VERSION ""

NS_ :

BS_:

BU_:

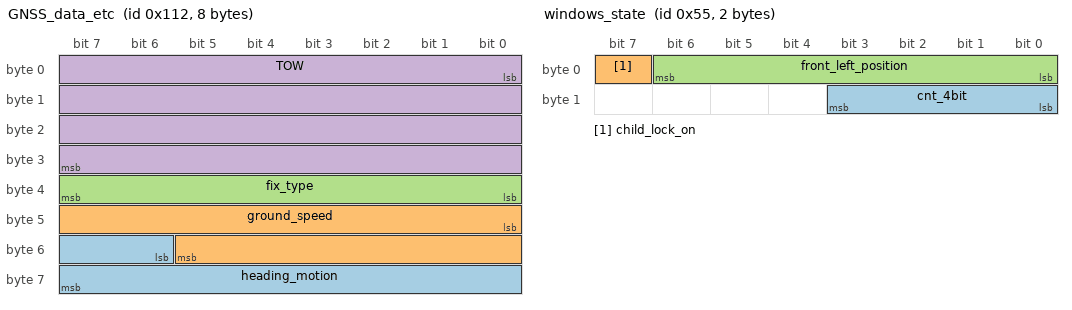
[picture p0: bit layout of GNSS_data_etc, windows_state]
BO_ 274 GNSS_data_etc: 8 Vector__XXX
 SG_ heading_motion : 54|10@1- (1,0) [-512|511] "" Vector__XXX
 SG_ ground_speed : 40|14@1- (0.08,0) [-655.36|655.28] "m/s" Vector__XXX
 SG_ fix_type : 32|8@1+ (1,0) [0|0] "" Vector__XXX
 SG_ TOW : 0|32@1+ (1,0) [0|0] "ms" Vector__XXX

BO_ 511 temperature: 2 Vector__XXX
 SG_ cnt_4bit : 12|4@1+ (1,0) [0|0] "" Vector__XXX
 SG_ temperature : 0|12@1- (0.1,100) [-104.8|304.7] "" Vector__XXX

BO_ 257 DTC_state: 3 Vector__XXX
 SG_ cnt_4bit : 16|4@1+ (1,0) [0|0] "" Vector__XXX
 SG_ stored_error_count : 0|16@1+ (1,0) [0|0] "" Vector__XXX

BO_ 256 error_event: 1 Vector__XXX
 SG_ error_code : 0|8@1+ (1,0) [0|0] "" Vector__XXX

BO_ 85 windows_state: 2 Vector__XXX
 SG_ cnt_4bit : 8|4@1+ (1,0) [0|0] "" Vector__XXX
 SG_ child_lock_on : 7|1@1+ (1,0) [0|0] "" Vector__XXX
 SG_ front_left_position : 0|7@1+ (1,0) [0|127] "%" Vector__XXX

BO_ 273 GNSS_data_pos: 8 Vector__XXX
 SG_ lon : 32|32@1- (1,0) [0|0] "" Vector__XXX
 SG_ lat : 0|32@1- (1,0) [0|0] "" Vector__XXX

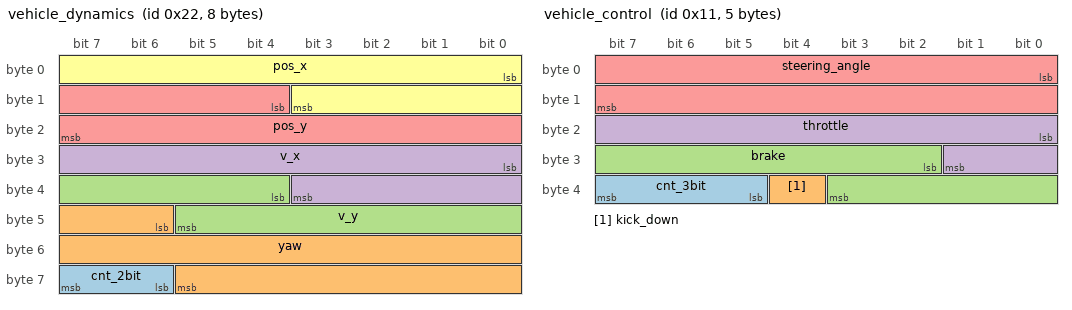
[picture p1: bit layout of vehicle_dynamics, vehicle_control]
BO_ 34 vehicle_dynamics: 8 Vector__XXX
 SG_ cnt_2bit : 62|2@1+ (1,0) [0|0] "" Vector__XXX
 SG_ yaw : 46|16@1- (0.015,0) [-491.52|491.505] "deg" Vector__XXX
 SG_ v_y : 36|10@1- (0.05,0) [-25.6|25.55] "m/s" Vector__XXX
 SG_ v_x : 24|12@1+ (0.1,0) [0|409.5] "m/s" Vector__XXX
 SG_ pos_y : 12|12@1- (1,0) [-2048|2047] "m" Vector__XXX
 SG_ pos_x : 0|12@1- (1,0) [-2048|2047] "m" Vector__XXX

BO_ 17 vehicle_control: 5 Vector__XXX
 SG_ cnt_3bit : 37|3@1+ (1,0) [0|0] "" Vector__XXX
 SG_ kick_down : 36|1@1+ (1,0) [0|0] "" Vector__XXX
 SG_ brake : 26|10@1+ (0.1,0) [0|102.3] "%" Vector__XXX
 SG_ throttle : 16|10@1+ (0.1,0) [0|102.3] "%" Vector__XXX
 SG_ steering_angle : 0|16@1- (0.04,0) [-1310.72|1310.68] "deg" Vector__XXX

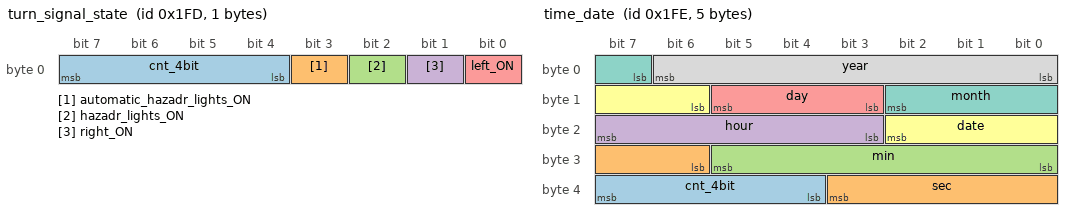
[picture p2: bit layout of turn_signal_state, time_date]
BO_ 509 turn_signal_state: 1 Vector__XXX
 SG_ cnt_4bit : 4|4@1+ (1,0) [0|0] "" Vector__XXX
 SG_ automatic_hazadr_lights_ON : 3|1@1+ (1,0) [0|0] "" Vector__XXX
 SG_ hazadr_lights_ON : 2|1@1+ (1,0) [0|0] "" Vector__XXX
 SG_ right_ON : 1|1@1+ (1,0) [0|0] "" Vector__XXX
 SG_ left_ON : 0|1@1+ (1,0) [0|0] "" Vector__XXX

BO_ 510 time_date: 5 Vector__XXX
 SG_ cnt_4bit : 36|4@1+ (1,0) [0|0] "" Vector__XXX
 SG_ sec : 30|6@1+ (1,0) [0|0] "" Vector__XXX
 SG_ min : 24|6@1+ (1,0) [0|0] "" Vector__XXX
 SG_ hour : 19|5@1+ (1,0) [0|0] "" Vector__XXX
 SG_ day : 11|3@1+ (1,0) [0|0] "" Vector__XXX
 SG_ date : 14|5@1+ (1,0) [0|0] "" Vector__XXX
 SG_ month : 7|4@1+ (1,0) [0|0] "" Vector__XXX
 SG_ year : 0|7@1+ (1,0) [0|0] "" Vector__XXX

CM_ SG_ 510 year "Actual year from 2000";
BA_DEF_  "BusType" STRING ;
BA_DEF_DEF_  "BusType" "CAN";
SIG_VALTYPE_ 273 lon : 1;
SIG_VALTYPE_ 273 lat : 1;
